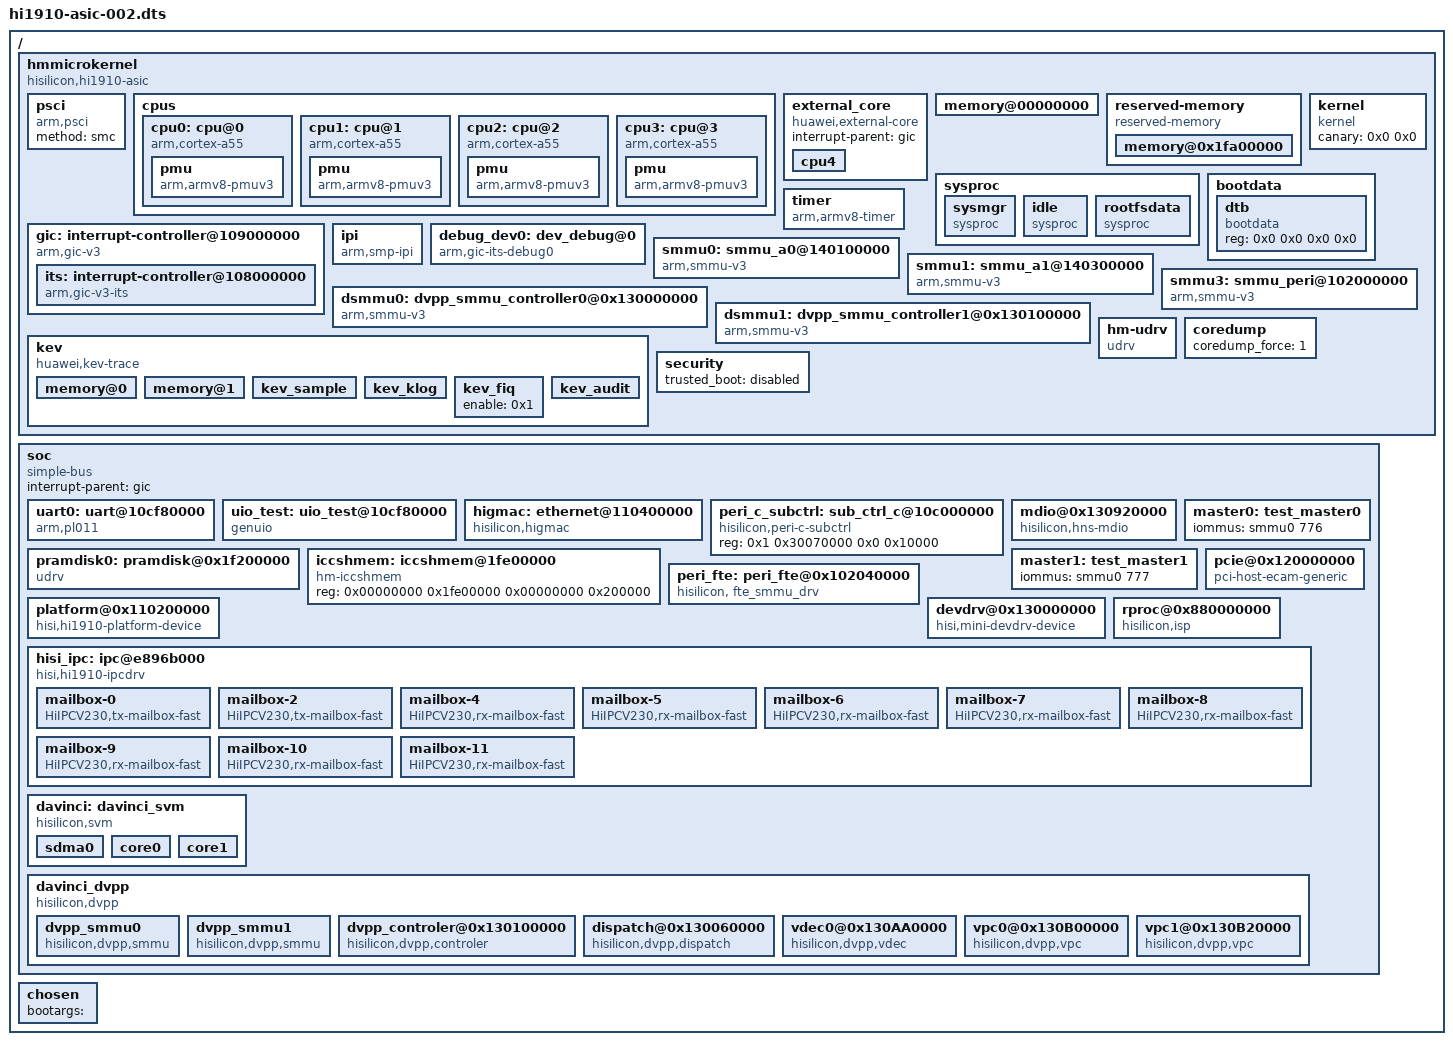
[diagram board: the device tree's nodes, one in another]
/dts-v1/;

/ {
	#address-cells = <2>; #size-cells = <2>; hmmicrokernel {
	compatible = "hisilicon,hi1910-asic", "hisilicon,hi1910";
	hisi,boardid = <0 0 0 2>;
	hisi,slotid = <0 0 0 0>;
	interrupt-parent = <&gic>;
	#address-cells = <2>;
	#size-cells = <2>;
	model = "Hisilicon PhosphorHi1910";

	psci {
		compatible = "arm,psci";
		method = "smc";
	};

	cpus {
		#address-cells = <1>;
		#size-cells = <0>;
		cpu0: cpu@0 {
			compatible = "arm,cortex-a55", "arm,armv8";
			device_type = "cpu";
			logic_id = <0>;
			reg = <0x81080000>;
			pmu {
				compatible = "arm,armv8-pmuv3";
				interrupt-parent = <&gic>;
				/* PPI 23: PMUIRQ, level triggered, hwprio:0x60 */
				interrupts = <23 0x00000060 0xFFFFFFFF>;
			};

		};
		cpu1: cpu@1 {
			compatible = "arm,cortex-a55", "arm,armv8";
			device_type = "cpu";
			logic_id = <1>;
			reg = <0x81080100>;
			pmu {
				compatible = "arm,armv8-pmuv3";
				interrupt-parent = <&gic>;
				/* PPI 23: PMUIRQ, level triggered, hwprio:0x60 */
				interrupts = <23 0x00000060 0xFFFFFFFF>;
			};

		};
		cpu2: cpu@2 {
			compatible = "arm,cortex-a55", "arm,armv8";
			device_type = "cpu";
			logic_id = <2>;
			reg = <0x81080200>;
			pmu {
				compatible = "arm,armv8-pmuv3";
				interrupt-parent = <&gic>;
				/* PPI 23: PMUIRQ, level triggered, hwprio:0x60 */
				interrupts = <23 0x00000060 0xFFFFFFFF>;
			};

		};
		cpu3: cpu@3 {
			compatible = "arm,cortex-a55", "arm,armv8";
			device_type = "cpu";
			logic_id = <3>;
			reg = <0x81080300>;
			pmu {
				compatible = "arm,armv8-pmuv3";
				interrupt-parent = <&gic>;
				/* PPI 23: PMUIRQ, level triggered, hwprio:0x60 */
				interrupts = <23 0x00000060 0xFFFFFFFF>;
			};

		};
	};

	external_core {
		compatible = "huawei,external-core";
		interrupt-parent = <&gic>;
		cpu4 {
			logic_extcore_id = <0>;
			mpidr = <0x81090000>;
		};
	};

	memory@00000000 {
		device_type = "memory";
		reg = <0x00000000 0x07e00000 0x00000000 0x17400000>,
		      <0x00000000 0x20000000 0x00000000 0x40000000>,
		      <0x00000000 0x62000000 0x00000000 0x1e000000>,
		      <0x00000008 0x80090000 0x00000001 0x7fb70000>;
	};

	/* The reserved memory is taken from the whole system memory. */
	reserved-memory {
		compatible = "reserved-memory";
		#address-cells = <2>;
		#size-cells = <2>;
		memory@0x1fa00000 {
			id = <0x0>;
			reg = <0x9 0xffc00000 0x0 0x400000>;
			alignment = <0x1000>;
		};
	};

	sysproc {
		#address-cells = <2>;
		#size-cells = <2>;
		sysmgr {
			compatible = "sysproc", "sysmgr";
			/* filled by bootloader */
			reg      = <0x0 0x0 0x0 0x0>;
			vphdr    = <0x0 0x0>;
			ventry   = <0x0 0x0>;
			pvoffset = <0x0 0x0>;
			nphdrs   = <0>;
			stack_start = <0x0 0x0>;
			stack_end = <0x0 0x0>;
			canary = <0x0 0x0>;
		};

		idle {
			compatible = "sysproc", "idle";
			/* filled by bootloader */
			reg      = <0x0 0x0 0x0 0x0>;
			vphdr    = <0x0 0x0>;
			ventry   = <0x0 0x0>;
			pvoffset = <0x0 0x0>;
			nphdrs   = <0>;
			stack_start = <0x0 0x0>;
			stack_end = <0x0 0x0>;
			canary = <0x0 0x0>;
		};

		rootfsdata {
			compatible = "sysproc", "rootfs";
			reg = <0x8 0x80004000 0x0 0x40000000>;
			ventry = <0x0 0x0>;
			/* filled by bootloader */
			pvoffset = <0x0 0x0>;
		};
	};

	kernel {
		compatible = "kernel";
		/* filled by bootloader */
		canary = <0x0 0x0>;
	};

	bootdata {
		#address-cells = <2>;
		#size-cells = <2>;
		dtb {
			compatible = "bootdata", "dtb";
			/* filled by bootloader */
			reg = <0x0 0x0 0x0 0x0>;
		};
	};

	timer {
		compatible = "arm,armv8-timer";
		clock-frequency = <19200000>;

		/* interrupt settings */
		interrupt-parent = <&gic>;

		/* PPI 30: Non-secure physical timer
		 * level triggered, hwprio:0x60 */
		interrupts = <30 0x00000060 0xFFFFFFFF>,
			     <26 0x00000060 0xFFFFFFFF>;
	};

	/* See Documentation/dts-gic.md for interrupts and distributor_config */
	gic: interrupt-controller@109000000 {
		compatible = "arm,gic-v3";

		#address-cells = <2>;
		#size-cells = <2>;

		/* Enable group 0, Group1NS, Group1S, ARE_NS, ARE_S,
		 * Split EOI and Deactive Mode */
		distributor-config = <0x80000037>;

		#interrupt-cells = <3>;
		#redistributor-regions = <1>;
		redistributor-stride = <0x20000>;
		interrupt-controller;

		reg =	<0x1 0x09000000 0x0 0x10000>,	/* GICD */
			<0x1 0x09100000 0x0 0x800000>;	/* GICR */
		alignment = <0x100000 0x100000>;

		interrupts = <25 0x000000E0 0xFFFFFFFF>;

		/* We haven't support this */
		its: interrupt-controller@108000000 {
			compatible = "arm,gic-v3-its";
			msi-controller;
			reg = <0x1 0x08000000 0x0 0x1000000>;
			alignment = <0x100000>;
			#interrupt-cells = <4>;
		};
	};

	ipi {
		/* smp ipi */
		compatible = "arm,smp-ipi";

		interrupt-parent = <&gic>;

		/* interrupt settings:
		 * 1st cell: real hardware irq number
		 *     ARM recommendation: ID 0-7 for Non-Secure;
		 *                         ID 8-15 for Secure Interrupt
		 * 2nd cell: interrupt config
		 *     bit [27:26]: Group setting
		 *     bit [24]: Trigger Type
		 *     bit [23:8]: Reserved
		 *     bit [7:0]: Priority
		 * 3rd cell: interrupt target config
		 *     Warning: Send to all cpus by default
		 */
		interrupts =	<0 0x00000060 0xFFFFFFFF>, /* IPI_RESCHEDULE */
				<1 0x00000060 0xFFFFFFFF>; /* IPI_CALL_FUNC */
	};

	/* used to debug its driver */
	debug_dev0:dev_debug@0 {
		compatible = "arm,gic-its-debug0";
		interrupts =	<0x245 0 0xE0 0>,
				<0x245 7 0xE0 0>,
				<0x245 14 0xE0 0>,
				<0x245 23 0xE0 0>;
		msi-parent = <&its>;
	};

	smmu0:smmu_a0@140100000 {
		compatible = "arm,smmu-v3";

		reg = <0x1 0x40100000 0x0 0x20000>;
		alignment = <0x10000>;
		smmu-controller;

		interrupt-parent = <&gic>;
		interrupts =	<493 0x02000060 0x00000001>,
				<494 0x02000060 0x00000001>,
				<495 0x02000060 0x00000001>;
		#iommu-cells = <0x1>;
		dma-coherent;
		hisilicon,broken-prefetch-cmd;
		hisilicon,broken-spi;
		#iommu-spi-base = <0x1 0x9000040>;
	};

	smmu1:smmu_a1@140300000 {
		compatible = "arm,smmu-v3";

		reg = <0x1 0x40300000 0x0 0x20000>;
		alignment = <0x10000>;
		smmu-controller;

		interrupt-parent = <&gic>;
		interrupts =	<504 0x02000060 0x00000001>,
				<505 0x02000060 0x00000001>,
				<506 0x02000060 0x00000001>;
		#iommu-cells = <0x1>;
		dma-coherent;
		hisilicon,broken-prefetch-cmd;
		hisilicon,broken-spi;
		#iommu-spi-base = <0x1 0x9000040>;
	};

	smmu3: smmu_peri@102000000 {
		compatible = "arm,smmu-v3";
		reg = <0x1 0x02000000 0x0 0x20000>;
		alignment = <0x10000>;
		smmu-controller;

		interrupt-parent = <&gic>;
		interrupts =	<67 0x02000060 0x00000001>, // 67 - event_ns
				<68 0x02000060 0x00000001>, // 68 - gerror_ns
				<69 0x02000060 0x00000001>; // 69 - sync_ns

		#iommu-cells = <1>;
		dma-coherent;
		hisilicon,broken-prefetch-cmd;
		hisilicon,broken-spi;
		#iommu-spi-base = <0x1 0x9000040>;
	};

	dsmmu0: dvpp_smmu_controller0@0x130000000 {
		// for B300: used for VPC0,1; PNGD0,1,2,3,4,5;
		compatible = "arm,smmu-v3";
		reg = <0x1 0x30000000 0x0 0x40000>;
		alignment = <0x10000>;
		smmu-controller;
		interrupt-parent = <&gic>;
		interrupts =	<353 0x00000060 0x00000001>,		// event_ns
				<354 0x00000060 0x00000001>,		// gerror_ns
				<355 0x00000060 0x00000001>;		// sync_ns
		#iommu-cells = <1>;
		dma-coherent;
		hisilicon,broken-prefetch-cmd;
		hisilicon,broken-spi;
		#iommu-spi-base = <0x1 0x09000040>;
	};

	dsmmu1: dvpp_smmu_controller1@0x130100000 {
		// for B300: used for FTE; JPEGE; JPEGD0,1; VDEC
		compatible = "arm,smmu-v3";
		reg = <0x1 0x30100000 0x0 0x40000>;
		alignment = <0x10000>;
		smmu-controller;
		interrupt-parent = <&gic>;
		interrupts =	<362 0x00000060 0x00000001>,		// event_ns
				<363 0x00000060 0x00000001>,		// gerror_ns
				<364 0x00000060 0x00000001>;		// sync_ns
		#iommu-cells = <1>;
		dma-coherent;
		hisilicon,broken-prefetch-cmd;
		hisilicon,broken-spi;
		#iommu-spi-base = <0x1 0x09000040>;
	};

	kev {
		compatible = "huawei,kev-trace";

		/*
		 * This is just a sample configuration. The ring buffer size is
		 * intentially set to a small value to pass the CI test which
		 * calls kev_print() to print ALL kev data in a panic test.
		 */
		memory@0 {
			type = <0x1>;
			id = <0x0>;
			ring-buffer-count = <0x4>;
			/*
			 * Only ring buffer DATA sizes. Memory head and ring
			 * buffer heads are not included.
			 * ring buffer 0: 256K
			 * ring buffer 1: 1M (perf)
			 * ring buffer 2: 256K
			 * ring buffer 3: 2M (klog)
			 */
			ring-buffer-sizes = <0x40000 0x100000 0x40000 0x200000>;
		};
		memory@1 {
			type = <0x0>;
			ring-buffer-count = <0x1>;
			/*
			 * ring buffer 4: 16K(audit)
			 */
			ring-buffer-sizes = <0x4000>;
		};
		kev_sample {
			config = <0x2>;
			enable = <0x1>;
		};
		kev_klog {
			config = <0x8>;
			enable = <0x1>;
		};
		kev_fiq {
			enable = <0x1>;
		};
		kev_audit {
			config = <0x10>;
			enable = <0x1>;
		};
	};

	hm-udrv {
		compatible = "udrv";
		reg = <0x1 0x0cf80000 0x0 0x010000>,
		      <0x1 0x10400000 0x0 0x010000>,
		      <0x1 0x100c0000 0x0 0x010000>,
		      <0x1 0x0cf00000 0x0 0x001000>,
		      <0x1 0x30920000 0x0 0x001000>,
		      <0x1 0x02040000 0x0 0x010000>,
		      <0x1 0x0c000000 0x0 0x010000>,
		      <0x1 0x20000000 0x0 0x100000>,
		      <0x1 0x10800000 0x0 0x800000>,
		      <0x1 0x10200000 0x0 0x200000>,
		      <0x1 0x10100000 0x0 0x1000>,
		      <0x0 0x0 0x0 0x900000>,
		      <0x1 0x30800000 0x0 0x5000>,
		      <0x1 0x30820000 0x0 0x5000>,
		      <0x1 0x30840000 0x0 0x5000>,
		      <0x1 0x30860000 0x0 0x5000>,
		      <0x1 0x0cd20000 0x0 0x5000>,
		      <0x1 0x0cd40000 0x0 0x5000>,
		      <0x1 0x0cd60000 0x0 0x5000>,
		      <0x1 0x0cd80000 0x0 0x5000>,
		      <0x1 0x02090000 0x0 0x1000>,
		      <0x8 0x80000000 0x0 0x20000>,
		      <0x0 0xc0200000 0x0 0xe00000>,
		      <0x0 0x60000000 0x0 0x2000000>,   /* TS_SQ */
		      <0x1 0xF0030000 0x0 0x10000>,  /* 1 TS_SUBSYSCTL */
		      <0x1 0xF0400000 0x0 0x400000>, /* 2 TS_DOORBELL */
		      <0x1 0xF0200000 0x0 0x10000>,  /* 3 TS_SRAM */
		      <0x1 0x02060000 0x0 0x10000>,  /* 4 Dispatch */
		      <0x1 0x000A0000 0x0 0x10000>,   /* 6 MN */
		      <0x1 0x000E0000 0x0 0x10000>,  /* 9 FIRMWARE_CLUSTER0_SUBCTRL_PHYS */
		      <0x8 0x80080000 0x0 0x10000>,  /* 10 TSCPU_FIRMWARE_CORE_RESET_ENTRY */
		      <0x0 0x00A20000 0x0 0x1000>,   /* 11 TSENSOR_SHAREMEM */
		      <0x0 0x009FE000 0x0 0x2000>,   /* 12 SYSTEM CONFIG BASE */
		      <0x2 0x00000000 0x0 0x800000>, /* L2BUF */
		      <0x1 0x30000000 0x0 0x40000>,
		      <0x1 0x30100000 0x0 0x40000>,
		      <0x1 0x30070000 0x0 0x10000>,
		      <0x1 0x30050000 0x0 0x10000>,
		      <0x1 0x30150000 0x0 0x10000>,
		      <0x1 0x30060000 0x0 0x10000>,
		      <0x1 0x30AA0000 0x0 0x10000>,
		      <0x1 0x30A80000 0x0 0x1000>,
		      <0x1 0x30A88000 0x0 0x1000>,
		      <0x1 0x30A8a000 0x0 0x1000>,
		      <0x1 0x30A82000 0x0 0x2000>,
		      <0x1 0x30A8b000 0x0 0x1000>,
		      <0x1 0x30B00000 0x0 0x20000>,
		      <0x1 0x30B20000 0x0 0x20000>,
		      <0x1 0x30a00000 0x0 0x10000>,
		      <0x1 0x30A10000 0x0 0x10000>,
		      <0x1 0x30A20000 0x0 0x10000>,
		      <0x1 0x30A30000 0x0 0x10000>,
		      <0x1 0x30A40000 0x0 0x10000>,
		      <0x1 0x30A50000 0x0 0x10000>,
		      <0x1 0x30C00000 0x0 0x40000>;

		interrupts =	<0x0000 32  0x000000E0 0xFFFFFFFF>,
				<0x0008 32  0x000000E0 0xFFFFFFFF>;
		msi-parent = <&its>;
	};

	coredump {
		coredump_force = <1>;
	};
	security {
		trusted_boot = "disabled";
	};
	};

	soc {
		compatible = "simple-bus";
		#address-cells = <2>;
		#size-cells = <2>;
		interrupt-parent = <&gic>;
		ranges;

		uart0: uart@10cf80000 {
			compatible = "arm,pl011", "arm,pl011,uart";
			reg = <0x1 0x0cf80000 0x0 0x10000>;
			alignment = <0x1000>;

			/* kernel control input */
			kernel-input;
			/* enable fifo */
			fifo-enabled;

			clock_frequency = <200000000>; /* 200MHz */
			interrupt-parent=<&gic>;
			interrupts=<357 0x00000060 0x00000001>;
		};

		uio_test: uio_test@10cf80000 {
			compatible = "genuio";
			reg = <0x1 0x0cf80000 0x0 0x10000>;
			alignment = <0x1000>;
		};

		higmac: ethernet@110400000 {
			compatible = "hisilicon,higmac";
			reg = <0x01 0x10400000 0x0 0x10000>,
				<0x01 0x100c0000 0x0 0x10000>,
				<0x01 0x0cf00000 0x0 0x1000>;
			alignment = <0x1000>;
			interrupt-parent = <&gic>;
			interrupts = <234 0x000000E0 0x1>;
			#address-cells = <0x1>;
			#size-cells = <0x0>;
			platform-type = <0x0>;
			phy-mode = "rgmii";
			dma-coherent;
			mac-where = <0x1>;
			mac-address = [00 00 00 00 00 00];
		};

		peri_c_subctrl: sub_ctrl_c@10c000000 {
			compatible = "hisilicon,peri-c-subctrl", "syscon";
			reg = <0x1 0x30070000 0x0 0x10000>;
		};

		mdio@0x130920000 {
			#address-cells = <1>;
			#size-cells = <0>;
			compatible = "hisilicon,hns-mdio";
			reg = <1 0x30920000 0 0x1000>;
			subctrl-vbase = <&peri_c_subctrl 0x630 0xd30 0x5630 0x5d30>;
			alignment = <0x1000>;
			gpio-type = <0x0>;
		};

		pramdisk0: pramdisk@0x1f200000 {
			compatible = "udrv", "hm-pramdisk", "hm-reserved-memory";
			reg = <0x00000000 0x1f200000 0x00000000 0x0800000>;
		};

		iccshmem: iccshmem@1fe00000 {
			compatible = "hm-iccshmem";
			reg = <0x00000000 0x1fe00000 0x00000000 0x200000>;
		};

		master0: test_master0 {
			iommus = <&smmu0 776>;
		};

		master1: test_master1 {
			iommus = <&smmu0 777>;
		};

		peri_fte: peri_fte@0x102040000 {
			compatible = "hisilicon, fte_smmu_drv";
			iommus = <&smmu0 0x7f8a>;
			alignment = <0x1000>;
		};
		pcie@0x120000000 {
			compatible = "pci-host-ecam-generic", "udrv";
			reg =  <0x1 0x20000000 0x0 0x100000>;
			reg-names = "ecam-cfg";
			device_type = "pci";
			bus-range = <0x00 0x00>;
			#interrupt-cells = <1>;
			msi-parent = <&its>;
			dma-coherent;
			#address-cells = <3>;
			#size-cells = <2>;
			ranges = <0x03000000 0x1 0x10800000 0x1 0x10800000 0 0x800000>;
			status = "ok";
		};

		/*pcie@0x110000000 {
			compatible = "hisi,hi1910-dma-pcie", "udrv";
			reg = <0x1 0x10200000 0 0x200000>;
			reg-names = "apb_base";
			status = "ok";
		};*/

		platform@0x110200000 {
			compatible = "hisi,hi1910-platform-device", "udrv";
			#address-cells = <0x2>;
			#size-cells = <0x2>;
			reg =	<0x1 0x10200000 0x0 0x200000>,
				<0x1 0x10100000 0x0 0x1000>,
				<0x0 0x0 0x0 0x900000>,
				<0x1 0x0c000000 0x0 0x4000>,
				<0x1 0x30800000 0x0 0x5000>,
				<0x1 0x30820000 0x0 0x5000>,
				<0x1 0x30840000 0x0 0x5000>,
				<0x1 0x30860000 0x0 0x5000>,
				<0x1 0x0cd20000 0x0 0x5000>,
				<0x1 0x0cd40000 0x0 0x5000>,
				<0x1 0x0cd60000 0x0 0x5000>,
				<0x1 0x0cd80000 0x0 0x5000>;
			reg-names = "apb_base", "gpio_base";
			interrupts =	<0xDA 0x000000E0 0x00000001>,
					<0xDB 0x000000E0 0x00000001>;
			status = "ok";
		};


	    devdrv@0x130000000 {
		compatible = "hisi,mini-devdrv-device", "udrv";
		#address-cells = <0x2>;
		#size-cells = <0x2>;
		reg = <0x1 0xF0030000 0x0 0x10000>,  /* 1 TS_SUBSYSCTL */
		      <0x1 0xF0400000 0x0 0x400000>, /* 2 TS_DOORBELL */
		      <0x1 0xF0200000 0x0 0x10000>,  /* 3 TS_SRAM */
		      <0x1 0x02060000 0x0 0x10000>,  /* 4 Dispatch */
		      <0x1 0x000A0000 0x0 0x1000>,   /* 6 MN */
		      <0x1 0x000E0000 0x0 0x10000>,  /* 9 FIRMWARE_CLUSTER0_SUBCTRL_PHYS */
		      <0x8 0x80080000 0x0 0x10000>,  /* 10 TSCPU_FIRMWARE_CORE_RESET_ENTRY */
		      <0x0 0x00A20000 0x0 0x1000>;  /* 11 TSENSOR_SHAREMEM */

		//l2buffer-region = <&l2buff>;
		dma-coherent;
		interrupts =	<278 0x000000E0 0x00000001>,
				<279 0x000000E0 0x00000001>,
				<280 0x000000E0 0x00000001>,
				<281 0x000000E0 0x00000001>,
				<282 0x000000E0 0x00000001>,
				<283 0x000000E0 0x00000001>,
				<284 0x000000E0 0x00000001>,
				<285 0x000000E0 0x00000001>,
				<286 0x000000E0 0x00000001>,
				<287 0x000000E0 0x00000001>,
				<288 0x000000E0 0x00000001>,
				<289 0x000000E0 0x00000001>,
				<290 0x000000E0 0x00000001>,
				<291 0x000000E0 0x00000001>,
				<292 0x000000E0 0x00000001>,
				<293 0x000000E0 0x00000001>,
				<294 0x000000E0 0x00000001>,
				<295 0x000000E0 0x00000001>,
				<296 0x000000E0 0x00000001>,
				<297 0x000000E0 0x00000001>,
				<298 0x000000E0 0x00000001>,
				<299 0x000000E0 0x00000001>,
				<300 0x000000E0 0x00000001>,
				<301 0x000000E0 0x00000001>,
				<302 0x000000E0 0x00000001>,
				<303 0x000000E0 0x00000001>,
				<304 0x000000E0 0x00000001>,
				<305 0x000000E0 0x00000001>,
				<306 0x000000E0 0x00000001>,
				<307 0x000000E0 0x00000001>,
				<308 0x000000E0 0x00000001>,
				<309 0x000000E0 0x00000001>,
				<273 0x000000E0 0x00000001>,
				<274 0x000000E0 0x00000001>,
				<159 0x000000E0 0x00000001>;
		status = "ok";


		aicpu,ts2ai_interrupt = <328>;
		aicpu,host_interrpt = <312>;
		aicpu,ipc_cpu_interrpt = <201>;
		aicpu,ipc_mbx_interrpt = <213>;
		aicpu,system_freq = <50000000>;

		aicpu,esl_occupy_bitmap = <0xF0>;
		aicpu,emu_occupy_bitmap = <0xF0>;
		aicpu,fpga_occupy_bitmap = <0x0C>;
		aicpu,asic_occupy_bitmap = <0xF0>;

		};

		/include/ "hi1910-aicpu-drv.dtsi"

		rproc@0x880000000 {
			compatible = "hisilicon,isp", "udrv";
			reg =  <0x8 0x80000000 0x0 0x20000>,
			       <0x0 0xc0200000 0x0 0xe00000>;
			hisi,use_secisp = <1>;
			useloadbin = <0>;
			use-smmuv3-flag = <0>;
			isp-names = "ISPCPU";     /* Name of MPU */
			firmware-names = "isp_fw.elf"; /* Name of Firmware */
			#address-cells = <3>;
			#size-cells = <2>;
			status = "ok";
		};

		hisi_ipc: ipc@e896b000 {
			#address-cells = <2>;
			#size-cells = <2>;
			compatible = "hisi,hi1910-ipcdrv";
			reg = <0x1 0x02090000 0x0 0x1000>;
				interrupt-parent = <&gic>;
			interrupts =	<201 0x000000E0 0x00000001>,
					<202 0x000000E0 0x00000001>,
					<203 0x000000E0 0x00000001>,
					<204 0x000000E0 0x00000001>;
				/*ACPU0     ACPU1       ACPU2         ACPU3 */

			unlock_key = <0x1ACCE551>;
			capability = <8>;
			status = "ok";

			/*
			 * "func"
			 * <mbox_type, is_src_mbox, is_des_mbox>;
			 */
			/*tx mbx channel*/
			mailboxes = <10>;
			mailbox-0 {
				compatible = "HiIPCV230,tx-mailbox-fast";
				func = <1 1 0>;
				src_remote_processor = "HI1910_AICPU0";
				des_remote_processor = "HI1910_TS_MBX0";
				src_bit = <2>;
				des_bit = <0>;
				index = <0>;
				used = <1>;
			};

			mailbox-2 {
				compatible = "HiIPCV230,tx-mailbox-fast";
				func = <1 1 0>;
				src_remote_processor = "HI1910_AICPU1";
				des_remote_processor = "HI1910_LPM3_MBX2";
				src_bit = <3>;
				des_bit = <1>;
				index = <2>;
				used = <1>;
			};

			/*rx mbx channel*/
			mailbox-4 {
				compatible = "HiIPCV230,rx-mailbox-fast";
				func = <1 0 1>;
				interrupt-parent = <&gic>;
				interrupts = <213 0x000000E0 0x00000001>;
				src_remote_processor = "HI1910_TS_MBX4";
				des_remote_processor = "HI1910_AICPU0_MBX4";
				src_bit = <0>;
				des_bit = <2>;
				index = <4>;
				used = <1>;
			};

			mailbox-5 {
				compatible = "HiIPCV230,rx-mailbox-fast";
				func = <1 0 1>;
				interrupt-parent = <&gic>;
				interrupts = <214 0x000000E0 0x00000001>;
				src_remote_processor = "HI1910_LPM3_MBX5";
				des_remote_processor = "HI1910_AICPU0_MBX5";
				src_bit = <1>;
				des_bit = <2>;
				index = <5>;
				used = <1>;
			};

			mailbox-6 {
				compatible = "HiIPCV230,rx-mailbox-fast";
				func = <1 0 1>;
				interrupt-parent = <&gic>;
				interrupts = <215 0x000000E0 0x00000001>;
				src_remote_processor = "HI1910_TS_MBX6";
				des_remote_processor = "HI1910_AICPU1_MBX6";
				src_bit = <0>;
				des_bit = <3>;
				index = <6>;
				used = <1>;
			};

			mailbox-7 {
				compatible = "HiIPCV230,rx-mailbox-fast";
				func = <1 0 1>;
				interrupt-parent = <&gic>;
				interrupts = <216 0x000000E0 0x00000001>;
				src_remote_processor = "HI1910_LPM3_MBX7";
				des_remote_processor = "HI1910_AICPU1_MBX7";
				src_bit = <1>;
				des_bit = <3>;
				index = <7>;
				used = <1>;
			};

			mailbox-8 {
				compatible = "HiIPCV230,rx-mailbox-fast";
				func = <1 0 1>;
				interrupt-parent = <&gic>;
				interrupts = <217 0x000000E0 0x00000001>;
				src_remote_processor = "HI1910_TS_MBX8";
				des_remote_processor = "HI1910_AICPU2_MBX8";
				src_bit = <0>;
				des_bit = <4>;
				index = <8>;
				used = <1>;
			};

			mailbox-9 {
				compatible = "HiIPCV230,rx-mailbox-fast";
				func = <1 0 1>;
				interrupt-parent = <&gic>;
				interrupts = <218 0x000000E0 0x00000001>;
				src_remote_processor = "HI1910_LPM3_MBX9";
				des_remote_processor = "HI1910_AICPU2_MBX9";
				src_bit = <1>;
				des_bit = <4>;
				index = <9>;
				used = <1>;
			};

			mailbox-10 {
				compatible = "HiIPCV230,rx-mailbox-fast";
				func = <1 0 1>;
				interrupt-parent = <&gic>;
				interrupts = <219 0x000000E0 0x00000001>;
				src_remote_processor = "HI1910_TS_MBX10";
				des_remote_processor = "HI1910_AICPU3_MBX10";
				src_bit = <0>;
				des_bit = <5>;
				index = <10>;
				used = <1>;
			};

			mailbox-11 {
				compatible = "HiIPCV230,rx-mailbox-fast";
				func = <1 0 1>;
				interrupt-parent = <&gic>;
				interrupts = <220 0x000000E0 0x00000001>;
				src_remote_processor = "HI1910_LPM3_MBX11";
				des_remote_processor = "HI1910_AICPU3_MBX11";
				src_bit = <1>;
				des_bit = <5>;
				index = <11>;
				used = <1>;
			};

			/*The mailbox-29 and mailbox-30  is comm-mailbox in SOC but fast-mailbox in software, define the src and des here, if need use, add it below*/
			/*******************maybe used in the future
			mailbox-30 {
				compatible = "HiIPCV230,mailbox-comm";
				func = <1 1 0>;
				src_remote_processor = "HI3650_GIC_2";
				des_remote_processor = "HI3650_LPM3_MBX30";
				src_bit = <1>;
				des_bit = <3>;
				index = <30>;
			};
			********************/
		};

		davinci:davinci_svm {
			compatible = "hisilicon,svm";

			sdma0 {
				iommus = <&smmu3 0x7f87>;
				dma-coherent;
				dma-can-stall;
				pasid-num-bits = <0x10>;
			};

			core0 {
				iommus = <&smmu0 0x7fa4>;
				dma-coherent;
				dma-can-stall;
				pasid-bits = <0x10>;
				pasid-num-bits = <0x10>;
			};

			core1 {
				iommus = <&smmu1 0x7fa5>;
				dma-coherent;
				dma-can-stall;
				pasid-bits = <0x10>;
				pasid-num-bits = <0x10>;
			};
		};

		davinci_dvpp {
			compatible = "hisilicon,dvpp";
			#address-cells = <0x2>;
			#size-cells = <0x2>;
			wakelock_name = "dvpp_wakelock_one";
			wakelock_timeout = <0xf>;
			interrupt-parent = <&gic>;

			dvpp_smmu0 {
				compatible = "hisilicon,dvpp,smmu";
				iommus = <&dsmmu0 0x7F91>;	// 0x7F9B is VPC0's sid in B300
				dma-coherent;
				dma-can-stall;
				pasid-num-bits = <16>;
			};

			dvpp_smmu1 {
				compatible = "hisilicon,dvpp,smmu";
				iommus = <&dsmmu1 0x7F9B>;	// 0x7F95 is FTE's sid in B300
				dma-coherent;
				dma-can-stall;
				pasid-num-bits = <16>;
			};

			dvpp_controler@0x130100000 {
				compatible = "hisilicon,dvpp,controler", "udrv";
				reg = <0x1 0x30000000 0x0 0x40000>,
				      <0x1 0x30100000 0x0 0x40000>,
				      <0x1 0x30070000 0x0 0x10000>,
				      <0x1 0x000a0000 0x0 0x10000>,
				      <0x1 0x30050000 0x0 0x10000>,
				      <0x1 0x30150000 0x0 0x10000>;
			};

			dispatch@0x130060000 {
				compatible = "hisilicon,dvpp,dispatch", "udrv";
				reg = <0x1 0x30060000 0x0 0x10000>;
				interrupts = <0x173 0x000000E0 0x00000001>;
			};

			vdec0@0x130AA0000 {
				compatible = "hisilicon,dvpp,vdec", "udrv";
				reg = <0x1 0x30AA0000 0x0 0x10000>;
				interrupts = <361 0x000000E0 0x00000001>;
				smmuflag = <0x0>;
			};

			vpc0@0x130B00000 {
				compatible = "hisilicon,dvpp,vpc", "udrv";
				reg = <0x1 0x30B00000 0x0 0x20000>;
				interrupts = <373 0x000000E0 0x00000001 374 0x000000E0 0x00000001>;
				smmuflag = <0x0>;
			};

			vpc1@0x130B20000 {
				compatible = "hisilicon,dvpp,vpc", "udrv";
				reg = <0x1 0x30B20000 0x0 0x20000>;
				interrupts = <375 0x000000E0 0x00000001 376 0x000000E0 0x00000001>;
				smmuflag = <0x0>;
			};
		};
	};

	chosen {
		 bootargs = "";
	};
};
